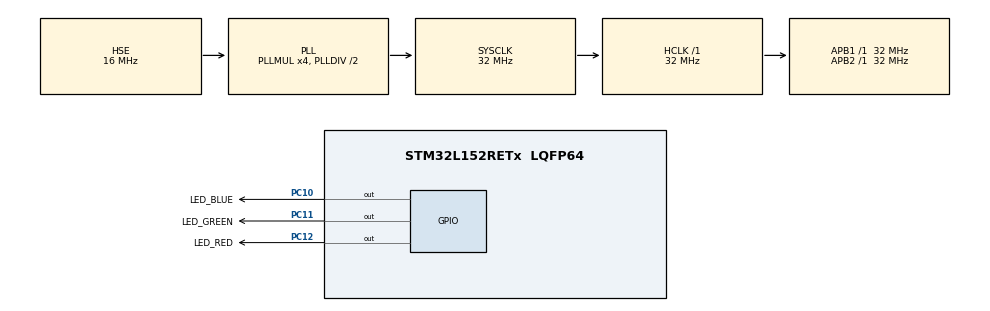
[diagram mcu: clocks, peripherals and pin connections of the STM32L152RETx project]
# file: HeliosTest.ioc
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FREERTOS.Tasks01=defaultTask,24,128,StartDefaultTask,Default,NULL,Dynamic,NULL,NULL
Mcu.Family=STM32L1
Mcu.Name=STM32L152RETx
Mcu.Package=LQFP64
NVIC.PriorityGroup=NVIC_PRIORITYGROUP_4
NVIC.TIM2_IRQn=true\:15\:0\:false\:false\:true\:false\:false\:true\:true
NVIC.TimeBase=TIM2_IRQn
NVIC.TimeBaseIP=TIM2
PA13.Mode=Trace_Asynchronous_SW
PA13.Signal=SYS_JTMS-SWDIO
PA14.Mode=Trace_Asynchronous_SW
PA14.Signal=SYS_JTCK-SWCLK
PB3.Mode=Trace_Asynchronous_SW
PB3.Signal=SYS_JTDO-TRACESWO
PC10.GPIO_Label=LED_BLUE
PC10.GPIO_PuPd=GPIO_NOPULL
PC10.Signal=GPIO_Output
PC11.GPIO_Label=LED_GREEN
PC11.Signal=GPIO_Output
PC12.GPIO_Label=LED_RED
PC12.Signal=GPIO_Output
PH0-OSC_IN.Mode=HSE-External-Oscillator
PH0-OSC_IN.Signal=RCC_OSC_IN
PH1-OSC_OUT.Mode=HSE-External-Oscillator
PH1-OSC_OUT.Signal=RCC_OSC_OUT
ProjectManager.HeapSize=0x200
ProjectManager.StackSize=0x400
ProjectManager.TargetToolchain=STM32CubeIDE
RCC.48MHZClocksFreq_Value=32000000
RCC.AHBFreq_Value=32000000
RCC.APB1Freq_Value=32000000
RCC.APB1TimFreq_Value=32000000
RCC.APB2Freq_Value=32000000
RCC.APB2TimFreq_Value=32000000
RCC.HCLKFreq_Value=32000000
RCC.HSE_VALUE=16000000
RCC.HSI_VALUE=16000000
RCC.LSE_VALUE=32768
RCC.MSI_VALUE=2097000
RCC.PLLMUL=RCC_PLL_MUL4
RCC.PLLSourceVirtual=RCC_PLLSOURCE_HSE
RCC.SYSCLKFreq_VALUE=32000000
RCC.SYSCLKSource=RCC_SYSCLKSOURCE_PLLCLK
RCC.VCOOutputFreq_Value=64000000
VP_FREERTOS_VS_CMSIS_V2.Mode=CMSIS_V2
VP_SYS_VS_tim2.Mode=TIM2
board=custom

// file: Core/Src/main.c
/* USER CODE BEGIN Header */
/**
  ******************************************************************************
  * @file           : main.c
  * @brief          : Main program body
  ******************************************************************************
  * @attention
  *
  * Copyright (c) 2022 STMicroelectronics.
  * All rights reserved.
  *
  * This software is licensed under terms that can be found in the LICENSE file
  * in the root directory of this software component.
  * If no LICENSE file comes with this software, it is provided AS-IS.
  *
  ******************************************************************************
  */
/* USER CODE END Header */
#include "main.h"
#include "cmsis_os.h"
#include "stdio.h"

/* USER CODE BEGIN PD */
#include"trcRecorder.h"
/* USER CODE END PD */

 /* Definitions for defaultTask */
osThreadId_t defaultTaskHandle;
const osThreadAttr_t defaultTask_attributes = {
  .name = "defaultTask",
  .stack_size = 128 * 4,
  .priority = (osPriority_t) osPriorityNormal,
};

void SystemClock_Config(void);
static void MX_GPIO_Init(void);
void StartDefaultTask(void *argument);

/* USER CODE BEGIN 0 */
int _write(int file, char *ptr, int len)
{
	int i=0;
	for (i=0; i<len; i++) {
		ITM_SendChar((*ptr++));
	}
	return len;
}

uint8_t count = 0;

/* USER CODE END 0 */

int main(void)
{

  /* MCU Configuration--------------------------------------------------------*/

  /* Reset of all peripherals, Initializes the Flash interface and the Systick. */
  HAL_Init();

  /* Configure the system clock */
  SystemClock_Config();

  /* USER CODE BEGIN SysInit */
  vTraceEnable(TRC_START);
  /* USER CODE END SysInit */

  /* Initialize all configured peripherals */
  MX_GPIO_Init();

  /* Init scheduler */
  osKernelInitialize();

  /* Create the thread(s) */
  /* creation of defaultTask */
  defaultTaskHandle = osThreadNew(StartDefaultTask, NULL, &defaultTask_attributes);

  /* Start scheduler */
  osKernelStart();

  /* We should never get here as control is now taken by the scheduler */
  /* Infinite loop */
  while (1)
  {

  }
}

void SystemClock_Config(void)
{
  RCC_OscInitTypeDef RCC_OscInitStruct = {0};
  RCC_ClkInitTypeDef RCC_ClkInitStruct = {0};

  /** Configure the main internal regulator output voltage
  */
  __HAL_PWR_VOLTAGESCALING_CONFIG(PWR_REGULATOR_VOLTAGE_SCALE1);

  /** Initializes the RCC Oscillators according to the specified parameters
  * in the RCC_OscInitTypeDef structure.
  */
  RCC_OscInitStruct.OscillatorType = RCC_OSCILLATORTYPE_HSE;
  RCC_OscInitStruct.HSEState = RCC_HSE_ON;
  RCC_OscInitStruct.PLL.PLLState = RCC_PLL_ON;
  RCC_OscInitStruct.PLL.PLLSource = RCC_PLLSOURCE_HSE;
  RCC_OscInitStruct.PLL.PLLMUL = RCC_PLL_MUL4;
  RCC_OscInitStruct.PLL.PLLDIV = RCC_PLL_DIV2;
  if (HAL_RCC_OscConfig(&RCC_OscInitStruct) != HAL_OK)
  {
    Error_Handler();
  }

  /** Initializes the CPU, AHB and APB buses clocks
  */
  RCC_ClkInitStruct.ClockType = RCC_CLOCKTYPE_HCLK|RCC_CLOCKTYPE_SYSCLK
                              |RCC_CLOCKTYPE_PCLK1|RCC_CLOCKTYPE_PCLK2;
  RCC_ClkInitStruct.SYSCLKSource = RCC_SYSCLKSOURCE_PLLCLK;
  RCC_ClkInitStruct.AHBCLKDivider = RCC_SYSCLK_DIV1;
  RCC_ClkInitStruct.APB1CLKDivider = RCC_HCLK_DIV1;
  RCC_ClkInitStruct.APB2CLKDivider = RCC_HCLK_DIV1;

  if (HAL_RCC_ClockConfig(&RCC_ClkInitStruct, FLASH_LATENCY_1) != HAL_OK)
  {
    Error_Handler();
  }
}

static void MX_GPIO_Init(void)
{
  GPIO_InitTypeDef GPIO_InitStruct = {0};

  /* GPIO Ports Clock Enable */
  __HAL_RCC_GPIOH_CLK_ENABLE();
  __HAL_RCC_GPIOA_CLK_ENABLE();
  __HAL_RCC_GPIOC_CLK_ENABLE();
  __HAL_RCC_GPIOB_CLK_ENABLE();

  /*Configure GPIO pin Output Level */
  HAL_GPIO_WritePin(GPIOC, LED_BLUE_Pin|LED_GREEN_Pin|LED_RED_Pin, GPIO_PIN_RESET);

  /*Configure GPIO pins : LED_BLUE_Pin LED_GREEN_Pin LED_RED_Pin */
  GPIO_InitStruct.Pin = LED_BLUE_Pin|LED_GREEN_Pin|LED_RED_Pin;
  GPIO_InitStruct.Mode = GPIO_MODE_OUTPUT_PP;
  GPIO_InitStruct.Pull = GPIO_NOPULL;
  GPIO_InitStruct.Speed = GPIO_SPEED_FREQ_LOW;
  HAL_GPIO_Init(GPIOC, &GPIO_InitStruct);

}

void StartDefaultTask(void *argument)
{
  /* USER CODE BEGIN 5 */
  /* Infinite loop */
  for(;;)
  {
    osDelay(200);
    HAL_GPIO_TogglePin(LED_GREEN_GPIO_Port, LED_GREEN_Pin);
    count++;
    printf(count);
  }
  /* USER CODE END 5 */
}

void HAL_TIM_PeriodElapsedCallback(TIM_HandleTypeDef *htim)
{
  if (htim->Instance == TIM2) {
    HAL_IncTick();
  }
}

void Error_Handler(void)
{
  __disable_irq();
  while (1)
  {
  }
}
